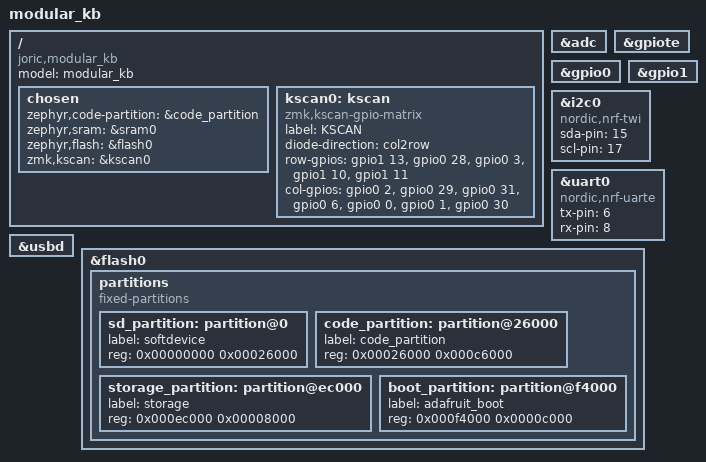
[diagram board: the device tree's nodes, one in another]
/*
 * Copyright (c) 2020 The ZMK Contributors
 *
 * SPDX-License-Identifier: MIT
 */

/dts-v1/;
#include <nordic/nrf52840_qiaa.dtsi>

/ {
	model = "modular_kb";
	compatible = "joric,modular_kb";

	chosen {
		zephyr,code-partition = &code_partition;
		zephyr,sram = &sram0;
		zephyr,flash = &flash0;
		zmk,kscan = &kscan0;
	};

	kscan0: kscan {
		compatible = "zmk,kscan-gpio-matrix";
		label = "KSCAN";
                diode-direction = "col2row";
		row-gpios
			= <&gpio1 13 (GPIO_ACTIVE_HIGH | GPIO_PULL_DOWN)>
			, <&gpio0 28 (GPIO_ACTIVE_HIGH | GPIO_PULL_DOWN)>
			, <&gpio0  3 (GPIO_ACTIVE_HIGH | GPIO_PULL_DOWN)>
			, <&gpio1 10 (GPIO_ACTIVE_HIGH | GPIO_PULL_DOWN)>
			, <&gpio1 11 (GPIO_ACTIVE_HIGH | GPIO_PULL_DOWN)>
			;
		col-gpios
			= <&gpio0  2 GPIO_ACTIVE_HIGH>
			, <&gpio0 29 GPIO_ACTIVE_HIGH>
			, <&gpio0 31 GPIO_ACTIVE_HIGH>
			, <&gpio0  6  GPIO_ACTIVE_HIGH>
			, <&gpio0  0  GPIO_ACTIVE_HIGH>
			, <&gpio0  1  GPIO_ACTIVE_HIGH>
			, <&gpio0 30  GPIO_ACTIVE_HIGH>
			;
	};
};

&adc {
	status = "okay";
};

&gpiote {
	status = "okay";
};

&gpio0 {
	status = "okay";
};

&gpio1 {
	status = "okay";
};

&i2c0 {
	compatible = "nordic,nrf-twi";
	sda-pin = <15>;
	scl-pin = <17>;
};

&uart0 {
	compatible = "nordic,nrf-uarte";
	tx-pin = <6>;
	rx-pin = <8>;
};

&usbd {
	status = "okay";
};


&flash0 {
	/*
	 * For more information, see:
	 * http://docs.zephyrproject.org/latest/devices/dts/flash_partitions.html
	 */
	partitions {
		compatible = "fixed-partitions";
		#address-cells = <1>;
		#size-cells = <1>;

		sd_partition: partition@0 {
			label = "softdevice";
			reg = <0x00000000 0x00026000>;
		};
		code_partition: partition@26000 {
			label = "code_partition";
			reg = <0x00026000 0x000c6000>;
		};

		/*
		 * The flash starting at 0x000ec000 and ending at
		 * 0x000f3fff is reserved for use by the application.
		 */

		/*
		 * Storage partition will be used by FCB/LittleFS/NVS
		 * if enabled.
		 */
		storage_partition: partition@ec000 {
			label = "storage";
			reg = <0x000ec000 0x00008000>;
		};

		boot_partition: partition@f4000 {
			label = "adafruit_boot";
			reg = <0x000f4000 0x0000c000>;
		};
	};
};

